# soc register map
Vendor: litex
Betrusted EC
Registers are 32-bit, read-write, reset 0x0 unless marked. A register's access mark holds for its fields unless they carry their own. Offsets are from the block's base; lines under a group give offsets from that group; [hi:lo] are bit positions; {n}, {i} and the like mark numbered series; 'fields as' and 'values as' point back to an identical list; <NAME> marks a mode.

## Memory map
0xF0000000 CRG size 0x4
0xF0000800 GIT size 0x8
0xF0001000 POWER size 0x8
0xF0002000 UART size 0x20
0xF0002800 PICORVSPI size 0xC
0xF0003000 I2C size 0x30
0xF0003800 TICKTIMER size 0x20
0xF0004000 COM size 0x8
0xF0004800 WIFI size 0x24
0xF0005000 CTRL size 0xC
0xF0005800 TIMER0 size 0x20

## Interrupts
0 timer0 (TIMER0)
1 uart (UART)
2 i2c (I2C)
3 ticktimer (TICKTIMER)
4 wifi (WIFI)

## Further device data
memoryRegions:
  SRAM baseAddress=0x10000000 size=0x00020000
  SPIFLASH baseAddress=0x20000000 size=0x00100000
  COM baseAddress=0xD0000000 size=0x00000004
  CSR baseAddress=0xF0000000 size=0x00010000
constants:
  CONFIG_CLOCK_FREQUENCY value=18000000
  CONFIG_CPU_HAS_INTERRUPT value=None
  CONFIG_CPU_RESET_ADDR value=536977408
  CONFIG_CPU_TYPE_VEXRISCV value=None
  CONFIG_CPU_VARIANT_MINIMAL value=None
  CONFIG_CPU_HUMAN_NAME value=VexRiscv_Min
  CONFIG_CPU_NOP value=nop
  CONFIG_CSR_DATA_WIDTH value=32
  CONFIG_CSR_ALIGNMENT value=32
  CONFIG_BUS_STANDARD value=WISHBONE
  CONFIG_BUS_DATA_WIDTH value=32
  CONFIG_BUS_ADDRESS_WIDTH value=32
  CONFIG_BUS_BURSTING value=0
  I2C_INTERRUPT value=2
  TICKTIMER_INTERRUPT value=3
  TIMER0_INTERRUPT value=0
  UART_INTERRUPT value=1
  WIFI_INTERRUPT value=4

## CRG
Base 0xF0000000
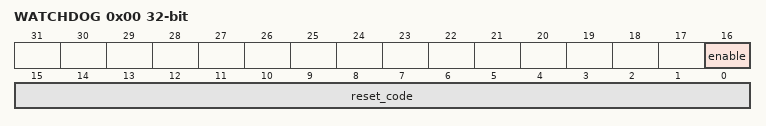
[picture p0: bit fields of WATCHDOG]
0x00 WATCHDOG
  [16] enable — Enable the watchdog timer. Cannot be disabled once enabled, except with a reset. Notably, a watchdog reset will disable the watchdog.
  [15:0] reset_code — Write `600d` then `c0de` in sequence to this register to reset the watchdog timer

## GIT
Base 0xF0000800
0x00 GITREV reset 0xA586F825 — First 32-bits of the git revision. This documentation was built from git rev ``a586f825``, so this value is 2777085989, which should be enough to check out the exact git version used to build this firmware.
0x04 DIRTY
  [0] dirty — Set to ``1`` if this device was built from a git repo with uncommitted modifications.

## POWER
Base 0xF0001000
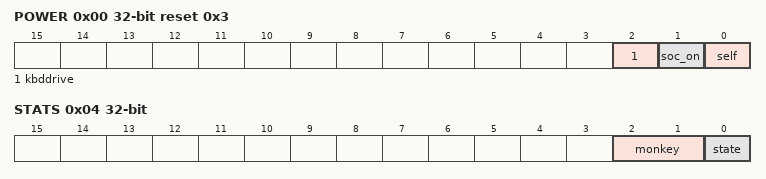
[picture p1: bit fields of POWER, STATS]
0x00 POWER reset 0x3
  [2] kbddrive — Writing `1` to this drives the scan column to 1. Do this prior to reading to mitigate noise
  [1] soc_on — Writing `1` to this powers on the SoC
  [0] self — Writing `1` to this keeps the EC powered on
0x04 STATS
  [2:1] monkey — Power-on key monitor input
  [0] state — Current power state of the SOC

## UART
Base 0xF0002000
0x00 RXTX
  [7:0] rxtx
0x04 TXFULL — TX FIFO Full.
  [0] txfull
0x08 RXEMPTY — RX FIFO Empty.
  [0] rxempty
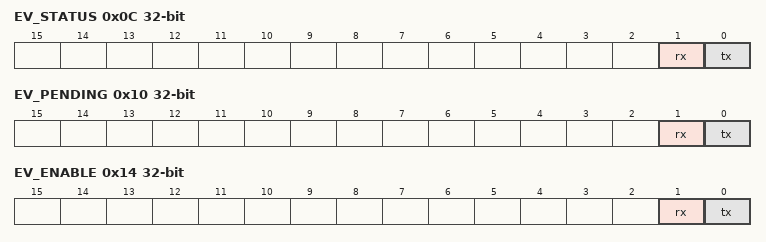
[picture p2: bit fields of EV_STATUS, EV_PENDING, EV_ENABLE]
0x0C EV_STATUS — This register contains the current raw level of the rx event trigger. Writes to this register have no effect.
  [1] rx — Level of the ``rx`` event
  [0] tx — Level of the ``tx`` event
0x10 EV_PENDING — When a rx event occurs, the corresponding bit will be set in this register. To clear the Event, set the corresponding bit in this register.
  [1] rx — `1` if a `rx` event occurred. This Event is triggered on a **falling** edge.
  [0] tx — `1` if a `tx` event occurred. This Event is triggered on a **falling** edge.
0x14 EV_ENABLE — This register enables the corresponding rx events. Write a ``0`` to this register to disable individual events.
  [1] rx — Write a ``1`` to enable the ``rx`` Event
  [0] tx — Write a ``1`` to enable the ``tx`` Event
0x18 TXEMPTY — TX FIFO Empty.
  [0] txempty
0x1C RXFULL — RX FIFO Full.
  [0] rxfull

## PICORVSPI
Base 0xF0002800
0x00 RDATA
  [3:0] data — Data bits from SPI [3:hold, 2:wp, 1:cipo, 0:copi]
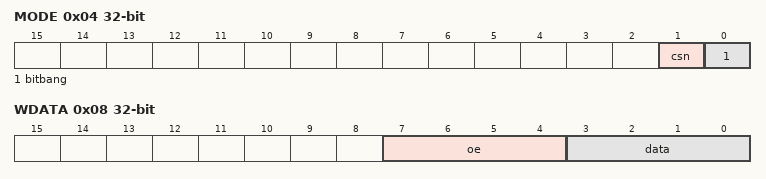
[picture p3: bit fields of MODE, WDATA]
0x04 MODE
  [1] csn — Chip select (set to `0` to select the chip)
  [0] bitbang — Turn on bitbang mode
0x08 WDATA — Writes to this field automatically pulse CLK
  [7:4] oe — Output enable for data pins
  [3:0] data — Data bits to SPI [3:hold, 2:wp, 1:cipo, 0:copi]
